# PCIe_SS1_EP_CFG_DBICS register map
Vendor: Texas Instruments
Peripheral module from a debugger description file (folder am572x).
Registers are 32-bit, access per field, reset 0x0 unless marked. A register's access mark holds for its fields unless they carry their own. Offsets are as the file gives them; lines under a group give offsets from that group; [hi:lo] are bit positions; {n}, {i} and the like mark numbered series; 'fields as' and 'values as' point back to an identical list; <NAME> marks a mode.

## PCIe_SS1_EP_CFG_DBICS
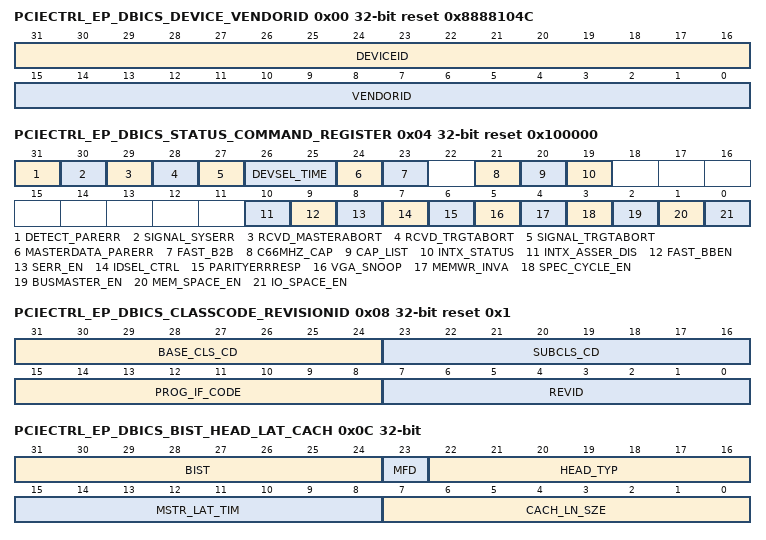
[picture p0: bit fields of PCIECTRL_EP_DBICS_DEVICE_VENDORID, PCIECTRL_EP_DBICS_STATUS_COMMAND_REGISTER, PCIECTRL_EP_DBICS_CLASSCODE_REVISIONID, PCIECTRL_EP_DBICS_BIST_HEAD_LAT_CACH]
0x00 PCIECTRL_EP_DBICS_DEVICE_VENDORID rw reset 0x8888104C — Device and Vendor ID
  [31:16] DEVICEID — Device ID (CS)
  [15:0] VENDORID — Vendor ID (CS)
0x04 PCIECTRL_EP_DBICS_STATUS_COMMAND_REGISTER reset 0x100000 — Status and Command registers
  [31] DETECT_PARERR rw — Detected Parity Error
  [30] SIGNAL_SYSERR rw — Signaled System Error
  [29] RCVD_MASTERABORT rw — Received Master Abort
  [28] RCVD_TRGTABORT rw — Received Target Abort
  [27] SIGNAL_TRGTABORT rw — Signaled Target Abort
  [26:25] DEVSEL_TIME ro — DevSel Timing, Harsdwired to 0 for PCIExpress
  [24] MASTERDATA_PARERR rw — Master Data Parity Error
  [23] FAST_B2B ro — Back to Back Capable, Harsdwired to 0 for PCIExpress
  [21] C66MHZ_CAP ro — 66MHz Capable, Harsdwired to 0 for PCIExpress
  [20] CAP_LIST ro — Capabilities List Hardwired to 1
  [19] INTX_STATUS ro
  [10] INTX_ASSER_DIS rw — INTx Assertion Disable
  [9] FAST_BBEN ro — Bit hardwired to 0 for PCIExpress
  [8] SERR_EN rw — SERR Enable
  [7] IDSEL_CTRL ro — Bit hardwired to 0 for PCIExpress
  [6] PARITYERRRESP rw — Parity Error Response
  [5] VGA_SNOOP ro — Not Applicable forPCI Express Bit hardwired to 0 for PCIExpress
  [4] MEMWR_INVA ro — Not Applicable for PCI Express Bit hardwired to 0 for PCIExpress
  [3] SPEC_CYCLE_EN ro — Not Applicable for PCI Express Bit hardwired to 0 for PCIExpress
  [2] BUSMASTER_EN rw — Bus Master Enable
  [1] MEM_SPACE_EN rw — Memory Space Enable
  [0] IO_SPACE_EN rw — IO Space Enable
0x08 PCIECTRL_EP_DBICS_CLASSCODE_REVISIONID rw reset 0x1 — Class code and Revision ID
  [31:24] BASE_CLS_CD — Base Class Code (CS)
  [23:16] SUBCLS_CD — Sub Class Code (CS)
  [15:8] PROG_IF_CODE — Programming Interface Code (CS)
  [7:0] REVID — Revision ID (CS)
0x0C PCIECTRL_EP_DBICS_BIST_HEAD_LAT_CACH — BIST, Header Type, Latency Timer, Cache Line Size
  [31:24] BIST ro
  [23] MFD ro — MultiFunction Device
  [22:16] HEAD_TYP ro — Header Type 0x0 = EP header 0x1 = RC header
  [15:8] MSTR_LAT_TIM ro — Master Latency Timer, Not Applicable for PCIe hence hardwired to 0
  [7:0] CACH_LN_SZE rw — Cache Line Size, No impact on write, write is allowed only for legacy purpose
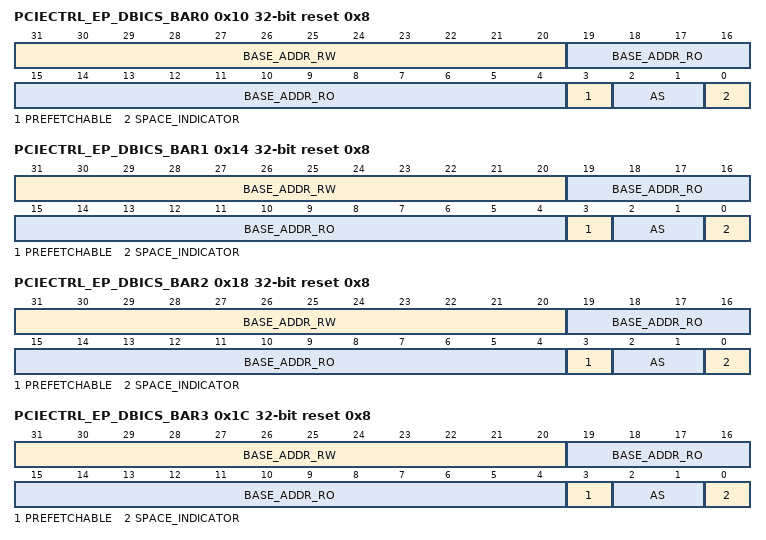
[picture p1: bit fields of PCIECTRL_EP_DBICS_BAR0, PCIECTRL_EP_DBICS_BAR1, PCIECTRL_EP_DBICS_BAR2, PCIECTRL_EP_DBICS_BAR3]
0x10 PCIECTRL_EP_DBICS_BAR0 reset 0x8 — Base Address Register 0 Bit #0 is also a WO BAR enable (CS2) BAR Mask is writable (CS2)
  [31:20] BASE_ADDR_RW rw — Base address bits (for a 64-bit BAR, upper base address bits are in BAR above). Unmasked MSBs, as set by BAR mask.
  [19:4] BASE_ADDR_RO ro — Base address bits (for a 64-bit BAR, upper base address bits are in BAR above). Masked LSBs, as set by BAR mask.
  [3] PREFETCHABLE rw — MEM BAR: Prefetchable (CS) I/O BAR: bit 1 is part of I/O address
  [2:1] AS rw — MEM BAR: Address Size (CS) I/O BAR: bit 0 is always 0, bit 1 is LSBit of I/O address Read 0x0 = 32 Bit Read 0x2 = 64 Bit
  [0] SPACE_INDICATOR rw — BAR I/O vs memory space indicator (CS) 0x0(R) = BAR type is Memory 0x1(R) = BAR type is I/O
0x14 PCIECTRL_EP_DBICS_BAR1 reset 0x8 — Base Address Register 1 If BAR0.AS = 64-bit: upper half of BAR0 base address If BAR0.AS = 32-bit: independent 32-bit BAR Bit #0 is also a WO BAR enable (CS2) BAR Mask is writable (CS2)
  [31:20] BASE_ADDR_RW rw — Base address bits (for a 64-bit BAR, lower base address bits are in BAR below). Unmasked MSBs, as set by BAR mask.
  [19:4] BASE_ADDR_RO ro — Base address bits (for a 64-bit BAR, lower base address bits are in BAR below). Masked LSBs, as set by BAR mask.
  [3] PREFETCHABLE rw — MEM BAR: Prefetchable (CS) I/O BAR: bit 1 is part of I/O address
  [2:1] AS rw — MEM BAR: Address Size (CS) I/O BAR: bit 0 is always 0, bit 1 is LSBit of I/O address Read 0x0 = 32 Bit Read 0x2 = 64 Bit
  [0] SPACE_INDICATOR rw — BAR I/O vs memory space indicator (CS) 0x0(R) = BAR type is Memory 0x1(R) = BAR type is I/O
0x18 PCIECTRL_EP_DBICS_BAR2 reset 0x8 — Base Address Register 2 Bit #0 is also a WO BAR enable (CS2) BAR Mask is writable (CS2)
  fields as PCIECTRL_EP_DBICS_BAR0
0x1C PCIECTRL_EP_DBICS_BAR3 reset 0x8 — Base Address Register 3 If BAR2.AS = 64-bit: upper half of BAR2 base address If BAR2.AS = 32-bit: independent 32-bit BAR Bit #0 is also a WO BAR enable (CS2) BAR Mask is writable (CS2)
  fields as PCIECTRL_EP_DBICS_BAR1
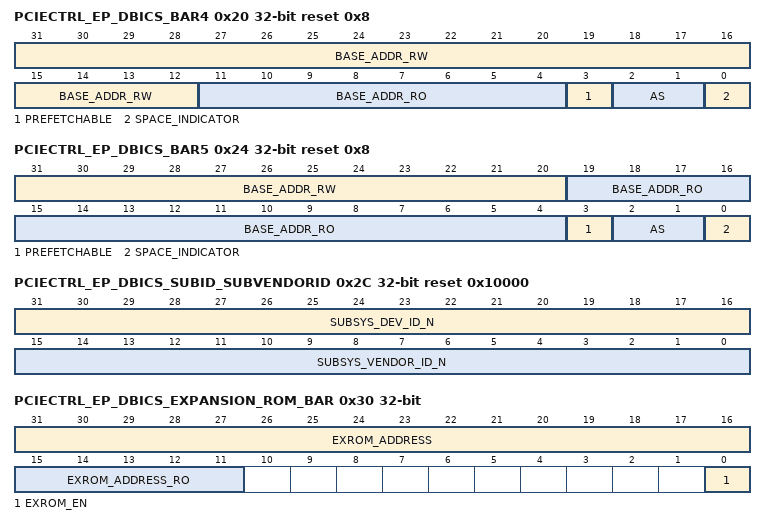
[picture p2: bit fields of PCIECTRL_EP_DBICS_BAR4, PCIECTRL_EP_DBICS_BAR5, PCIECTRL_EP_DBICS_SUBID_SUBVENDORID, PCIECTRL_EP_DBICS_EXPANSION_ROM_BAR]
0x20 PCIECTRL_EP_DBICS_BAR4 reset 0x8 — Base Address Register 4 Bit #0 is also a WO BAR enable (CS2) BAR Mask is writable (CS2)
  [31:12] BASE_ADDR_RW rw — Base address bits (for a 64-bit BAR, upper base address bits are in BAR above). Unmasked MSBs, as set by BAR mask.
  [11:4] BASE_ADDR_RO ro — Base address bits (for a 64-bit BAR, upper base address bits are in BAR above). Masked LSBs, as set by BAR mask.
  [3] PREFETCHABLE rw — MEM BAR: Prefetchable (CS) I/O BAR: bit 1 is part of I/O address
  [2:1] AS rw — MEM BAR: Address Size (CS) I/O BAR: bit 0 is always 0, bit 1 is LSBit of I/O address Read 0x0 = 32 Bit Read 0x2 = 64 Bit
  [0] SPACE_INDICATOR rw — BAR I/O vs memory space indicator (CS) 0x0(R) = BAR type is Memory 0x1(R) = BAR type is I/O
0x24 PCIECTRL_EP_DBICS_BAR5 reset 0x8 — Base Address Register 5 If BAR4.AS = 64-bit: upper half of BAR4 base address If BAR4.AS = 32-bit: independent 32-bit BAR Bit #0 is also a WO BAR enable (CS2) BAR Mask is writable (CS2)
  fields as PCIECTRL_EP_DBICS_BAR1
0x28 PCIECTRL_EP_DBICS_CARDBUS_CIS_POINTER rw
  [31:0] CARDBUS_CIS_PTR_N — Cardbus CIS pointer (CS)
0x2C PCIECTRL_EP_DBICS_SUBID_SUBVENDORID rw reset 0x10000
  [31:16] SUBSYS_DEV_ID_N — Subsystem ID (CS)
  [15:0] SUBSYS_VENDOR_ID_N — Subsystem Vendor ID (CS)
0x30 PCIECTRL_EP_DBICS_EXPANSION_ROM_BAR — Expansion ROM Base Address Register
  [31:16] EXROM_ADDRESS rw — Expansion ROM address, unmasked (ie programmable)
  [15:11] EXROM_ADDRESS_RO ro — Expansion ROM address, masked.
  [0] EXROM_EN rw — Expansion ROM Enable
0x34 PCIECTRL_EP_DBICS_CAPPTR reset 0x40 — CapPtr
  [7:0] CAPTR rw — First Capability Pointer (CS)
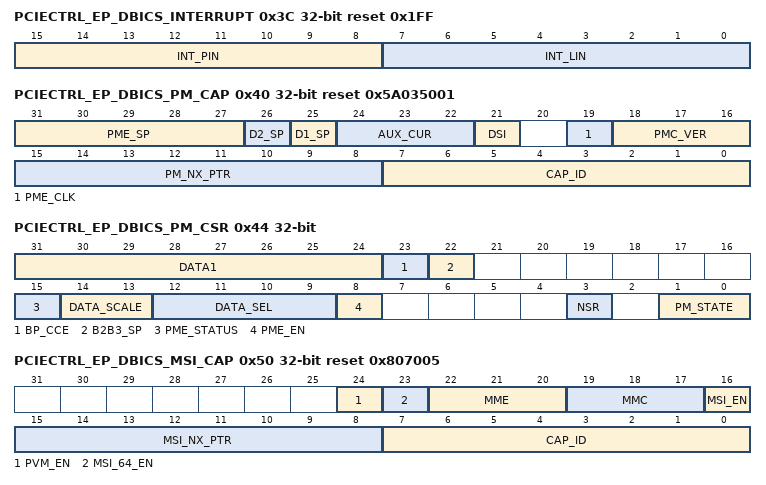
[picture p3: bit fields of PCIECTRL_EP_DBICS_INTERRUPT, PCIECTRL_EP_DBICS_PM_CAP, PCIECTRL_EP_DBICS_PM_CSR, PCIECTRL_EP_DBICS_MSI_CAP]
0x3C PCIECTRL_EP_DBICS_INTERRUPT reset 0x1FF — Int Pin and line
  [15:8] INT_PIN rw — Interrupt Pin (CS)
  [7:0] INT_LIN rw — Interrupt Line
0x40 PCIECTRL_EP_DBICS_PM_CAP reset 0x5A035001 — Power Management Capability structure header
  [31:27] PME_SP rw — PME Support (CS); Power states from which PME messages can be sent (active hi, one bit per state) Bit 0: from D0 Bit 1: from D1 Bit 2: from D2 Bit 3: from D3hot Bit 4: from D3cold (if Vaux present)
  [26] D2_SP rw — D2 Support (CS)
  [25] D1_SP rw — D1 Support (CS)
  [24:22] AUX_CUR rw — AUX Current (CS)
  [21] DSI rw — Device Specific Initialization (CS)
  [19] PME_CLK rw — PME Clock, hardwired to 0 (CS)
  [18:16] PMC_VER rw — Power Management specification version (CS)
  [15:8] PM_NX_PTR rw — Next Capability Pointer (CS)
  [7:0] CAP_ID ro — Capability ID
    1=PM
0x44 PCIECTRL_EP_DBICS_PM_CSR access not given — Power Management Control and Status Register
  [31:24] DATA1 ro — Data register for additional information (not supported)
  [23] BP_CCE ro — Bus Power/Clock Control Enable, hardwired to 0
  [22] B2B3_SP ro — B2/B3 Support, hardwired to 0
  [15] PME_STATUS — PME Status (Sticky bit) (access RW W1toClr)
  [14:13] DATA_SCALE ro — Data Scale (not supported)
  [12:9] DATA_SEL ro — Data Select (not supported)
  [8] PME_EN rw — PME Enable (Sticky bit)
    0=Device_not_enabled_to_generate_PME; 1=PME;_ON,_1 (Device enabled to generate PME; implies that Vaux is ON, ie sticky bits will be preserved over reset)
  [3] NSR rw — No Soft Reset (CS)
  [1:0] PM_STATE rw — Power Management Control and Status Register
    {v}=D{v}_state (v=0..3)
0x50 PCIECTRL_EP_DBICS_MSI_CAP reset 0x807005 — Message Signaled Interrupt Capability structure header
  [24] PVM_EN ro — MSI Per Vector Masking (PVM) supported
  [23] MSI_64_EN ro — 64-bit Address Capable (CS)
  [22:20] MME rw — Multiple Message Enable
  [19:17] MMC ro — Multiple Message Capable (CS)
  [16] MSI_EN rw — MSI Enable
  [15:8] MSI_NX_PTR ro — Next Capability Pointer (CS)
  [7:0] CAP_ID ro — MSI Capability ID Read 0x05 MSI
0x54 PCIECTRL_EP_DBICS_MSI_ADD_L32 — PCIe memory space address of MSI write TLP request, lower 32 bits.
  [31:2] ADDR rw — Lower 32-bit address (DWORD aligned)
0x58 PCIECTRL_EP_DBICS_MSI_ADD_U32 rw — PCIe memory space address of MSI write TLP request, upper 32 bits (used if MSI_64_EN = 1).
  [31:0] ADDR — Upper 32-bit address
0x5C PCIECTRL_EP_DBICS_MSI_DATA — Data of MSI write TLP request (modified for multiple vectors)
  [15:0] DATA rw — MSI data
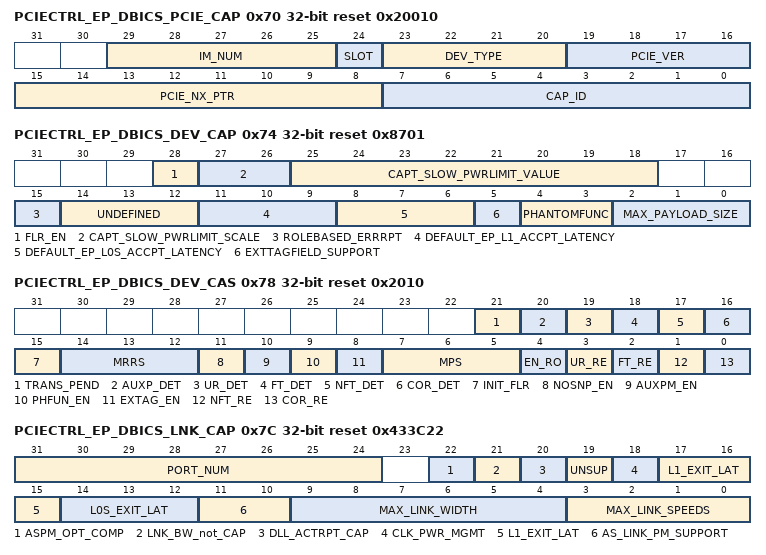
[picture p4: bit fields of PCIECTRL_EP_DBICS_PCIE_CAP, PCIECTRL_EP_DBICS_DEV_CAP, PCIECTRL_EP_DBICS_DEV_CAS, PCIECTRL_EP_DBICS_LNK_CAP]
0x70 PCIECTRL_EP_DBICS_PCIE_CAP reset 0x20010 — PCIE cap structure
  [29:25] IM_NUM rw — Interrupt Message Number (CS)
  [24] SLOT rw — Slot Implemented Must be 0 for an endpoint
  [23:20] DEV_TYPE ro — Device/Port Type Value depends on assigned type 0x0 = PCIe endpoint 0x1 = Legacy PCIe endpoint
  [19:16] PCIE_VER ro — PCI Express Capability Version
  [15:8] PCIE_NX_PTR rw — Next Capability Pointer (CS)
  [7:0] CAP_ID ro — Capability ID
0x74 PCIECTRL_EP_DBICS_DEV_CAP reset 0x8701 — PCIE Device Capabilities
  [28] FLR_EN rw — Function Level Reset Capability (CS)
  [27:26] CAPT_SLOW_PWRLIMIT_SCALE rw — Captured Slow Power Scale Value (CS)
  [25:18] CAPT_SLOW_PWRLIMIT_VALUE rw — Captured Slow Power Limit Value (CS)
  [15] ROLEBASED_ERRRPT rw — Role Based Error Reporting (CS)
  [14:12] UNDEFINED ro — Undefined from PCIe 1.1 onwards (CS)
  [11:9] DEFAULT_EP_L1_ACCPT_LATENCY ro — Endpoint L1 Acceptable Latency (CS)
  [8:6] DEFAULT_EP_L0S_ACCPT_LATENCY ro — Endpoint L0s Acceptable Latency (CS)
  [5] EXTTAGFIELD_SUPPORT rw — Value derived from DEFAULT_EXT_TAG_FIELD_SUPPORTED
  [4:3] PHANTOMFUNC rw — Phantom Function Support, not SUPPORTED (CS)
  [2:0] MAX_PAYLOAD_SIZE rw — Maximum Payload Size (CS) Read 0x1 = 256 Byte
0x78 PCIECTRL_EP_DBICS_DEV_CAS reset 0x2010 — PCIE Device Control and Status
  [21] TRANS_PEND ro — Transaction Pending
  [20] AUXP_DET ro — Aux Power Detected
  [19] UR_DET rw — Unsupported Request Detected
  [18] FT_DET rw — Fatal Error Detected
  [17] NFT_DET rw — Non-Fatal Error Detected
  [16] COR_DET rw — Correctable Error Detected
  [15] INIT_FLR ro — Reserved
  [14:12] MRRS rw — Max_Read_Request_Size
  [11] NOSNP_EN rw — Enable No Snoop
  [10] AUXPM_EN rw — AUX Power PM Enable
  [9] PHFUN_EN rw — Phantom Function Enable
  [8] EXTAG_EN rw — Extended Tag Field Enable
  [7:5] MPS rw — Max_Payload_Size
  [4] EN_RO rw — Enable Relaxed Ordering
  [3] UR_RE rw — Unsupported Request Reporting Enable
  [2] FT_RE rw — Fatal Error Reporting Enable
  [1] NFT_RE rw — Non-Fatal Error Reporting Enable
  [0] COR_RE rw — Correctable Error Reporting Enable
0x7C PCIECTRL_EP_DBICS_LNK_CAP reset 0x433C22 — PCIE Link Capabilities
  [31:24] PORT_NUM rw — Port Number (CS)
  [22] ASPM_OPT_COMP rw — ASPM Optionality Compliance (CS)
  [21] LNK_BW_not_CAP rw — Link Bandwidth Notification Capability (CS)
  [20] DLL_ACTRPT_CAP ro — Data Link Layer Active Reporting Capable
  [19] UNSUP ro — Unsupported, Surprise Down Error Reporting Capable, Hardwired to 0
  [18] CLK_PWR_MGMT rw — Clock Power Management (CS)
  [17:15] L1_EXIT_LAT ro — L1 Exit Latency (CS2)
  [14:12] L0S_EXIT_LAT ro — L0s Exit Latency (CS2)
  [11:10] AS_LINK_PM_SUPPORT rw — Active State Link PM (ASPM) Support (CS)
  [9:4] MAX_LINK_WIDTH rw — Max Link Width (lanes) (CS)
  [3:0] MAX_LINK_SPEEDS rw — Supported Max Link Speed (CS) 0x1(R) = 2.5 GT/s (Gen1) 0x2(R) = 5 GT/s (Gen2) 0x4(R) = 8 GT/s (Gen3)
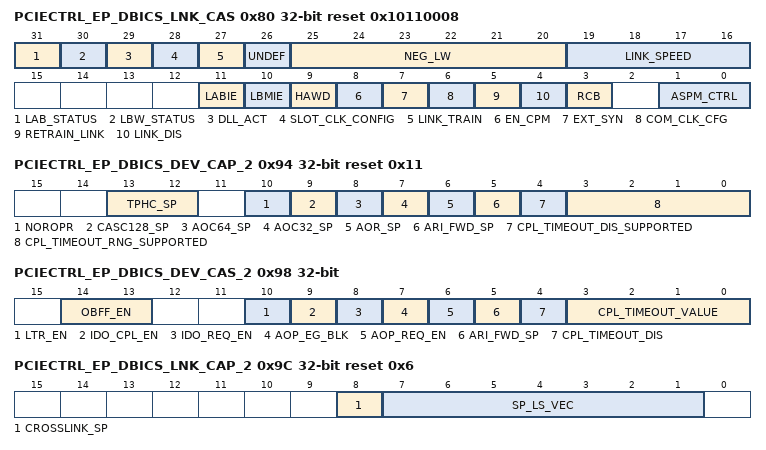
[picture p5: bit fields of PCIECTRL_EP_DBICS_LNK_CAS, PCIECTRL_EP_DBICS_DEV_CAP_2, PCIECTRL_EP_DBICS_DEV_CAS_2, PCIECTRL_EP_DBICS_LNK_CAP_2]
0x80 PCIECTRL_EP_DBICS_LNK_CAS reset 0x10110008 — PCIE Link Control and Status
  [31] LAB_STATUS ro — Link Autonomous Bandwidth Status
  [30] LBW_STATUS ro — Link Bandwidth Management Status
  [29] DLL_ACT ro — Data Link Layer Active
  [28] SLOT_CLK_CONFIG rw — Slot Clock Configuration (CS)
  [27] LINK_TRAIN ro — LINK training
  [26] UNDEF ro — Undefined
  [25:20] NEG_LW ro — Negotiated Link Width UNDEFINED UNTIL LINK IS UP.
  [19:16] LINK_SPEED ro — Link Speed UNDEFINED UNTIL LINK IS UP.
  [11] LABIE rw — Link Autonomous Bandwidth Interrupt Enable.
  [10] LBMIE rw — Link Bandwidth Management Interrupt Enable
  [9] HAWD ro — Hardware Autonomous Width Disable
  [8] EN_CPM rw — Enable Clock Power Management
  [7] EXT_SYN rw — Extended Synch
  [6] COM_CLK_CFG rw — Common Clock Configuration
  [5] RETRAIN_LINK ro
  [4] LINK_DIS ro — Link Disable
  [3] RCB rw — Read Completion Boundary (CS) 0x0 = 64 Byte 0x1 = 128 Byte
  [1:0] ASPM_CTRL rw — Active State Link PM Control 0x0: DISABLED 0x1: L0S_ENABLED 0x2: L1_ENABLED 0x3: L0S_AND_L1_ENABLED
0x94 PCIECTRL_EP_DBICS_DEV_CAP_2 ro reset 0x11 — Device Capabilities 2 Register
  [13:12] TPHC_SP — TPH Completer Supported
  [10] NOROPR — No RO-enabled PR-PR Passing
  [9] CASC128_SP — 128-bit CAS Completer Supported
  [8] AOC64_SP — 64-bit AtomicOp Completer Supported
  [7] AOC32_SP — 32-bit AtomicOp Completer Supported
  [6] AOR_SP — AtomicOp Routing Supported
  [5] ARI_FWD_SP — ARI Forwarding Supported
  [4] CPL_TIMEOUT_DIS_SUPPORTED — Completion Timeout Disable Supported
  [3:0] CPL_TIMEOUT_RNG_SUPPORTED — Completion Timeout Ranges Supported
0x98 PCIECTRL_EP_DBICS_DEV_CAS_2 — Device Control 2 Register
  [14:13] OBFF_EN rw — OBFF Enable
  [10] LTR_EN rw — LTR Mechanism Enable
  [9] IDO_CPL_EN rw — IDO Completion Enable
  [8] IDO_REQ_EN rw — IDO Request Enable
  [7] AOP_EG_BLK rw — AtomicOp Egress Blocking
  [6] AOP_REQ_EN rw — AtomicOp Requester Enable
  [5] ARI_FWD_SP rw — ARI Forwarding Supported
  [4] CPL_TIMEOUT_DIS rw — Completion Timeout Disable
  [3:0] CPL_TIMEOUT_VALUE rw — Completion Timeout Values
0x9C PCIECTRL_EP_DBICS_LNK_CAP_2 ro reset 0x6 — PCIE Link Capabilities 2 Register
  [8] CROSSLINK_SP — Crosslink Supported
  [7:1] SP_LS_VEC — Supported Link Speeds Vector
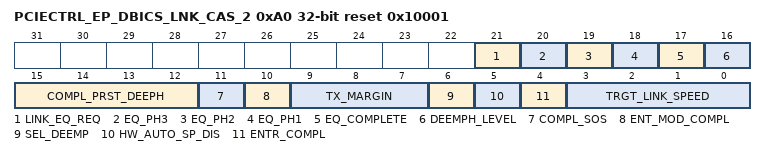
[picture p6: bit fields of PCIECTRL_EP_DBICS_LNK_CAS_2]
0xA0 PCIECTRL_EP_DBICS_LNK_CAS_2 access not given reset 0x10001 — Link Control and Status 2 Register
  [21] LINK_EQ_REQ — Link Equilization Request (access RW Wr1toClr)
  [20] EQ_PH3 ro — Equalization Ph3 Success, Gen3 Only
  [19] EQ_PH2 ro — Equalization Ph2 Success, Gen3 Only
  [18] EQ_PH1 ro — Equalization Ph1 Success, Gen3 Only
  [17] EQ_COMPLETE ro — Equalization Complete, Gen3 Only
  [16] DEEMPH_LEVEL ro — Current De-emphasis Level
  [15:12] COMPL_PRST_DEEPH rw — Compliance Pre-set/ De-emphasis
  [11] COMPL_SOS rw — Compliance SOS
  [10] ENT_MOD_COMPL rw — Enter Modified Compliance
  [9:7] TX_MARGIN rw — Transmit Margin
  [6] SEL_DEEMP ro — Selectable De-emphasize
  [5] HW_AUTO_SP_DIS ro — Hardware Autonomous Speed Disable
  [4] ENTR_COMPL rw — Enter Compliance
  [3:0] TRGT_LINK_SPEED rw — Target Link Speed
